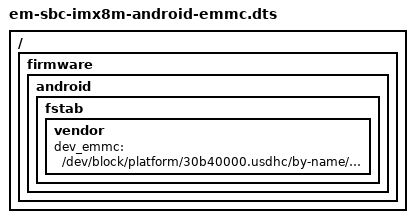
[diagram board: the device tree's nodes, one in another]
/*
 * Copyright 2019 EMBEST
 *
 * This program is free software; you can redistribute it and/or
 * modify it under the terms of the GNU General Public License
 * as published by the Free Software Foundation; either version 2
 * of the License, or (at your option) any later version.
 *
 * This program is distributed in the hope that it will be useful,
 * but WITHOUT ANY WARRANTY; without even the implied warranty of
 * MERCHANTABILITY or FITNESS FOR A PARTICULAR PURPOSE.  See the
 * GNU General Public License for more details.
 */

#include "em-sbc-imx8m-android.dts"

/ {
	firmware {
		android {
			fstab {
				vendor {
					/delete-property/ dev_sd;
					/* emmc node which used if androidboot.storage_type=emmc */
					dev_emmc = "/dev/block/platform/30b40000.usdhc/by-name/vendor";
				};
			};
		};
	};
};
